# ISD91000_v4_2 register map
File version: 1.0
ISD91000_v4_2 SVD file
Registers are 32-bit, read-write, reset 0x0 unless marked. A register's access mark holds for its fields unless they carry their own. Offsets are from the block's base; lines under a group give offsets from that group; [hi:lo] are bit positions; {n}, {i} and the like mark numbered series; 'fields as' and 'values as' point back to an identical list; <NAME> marks a mode.

## Memory map
0x40004000 WDT size 0x4 — WDT Register Map
0x40008000 RTC size 0x4 — RTC Register Map
0x40008004 OSCFM size 0xC — OSCFM Register Map
0x40010000 TMR blocks up to offset 0x50 — TMR Register Map
0x40030000 SPI0 blocks up to offset 0x3C — SPI Register Map
0x40070000 DPWM size 0x14 — DPWM Register Map
0x400E0000 ADC blocks up to offset 0x48 — ADC Register Map
0x50000000 SYS blocks up to offset 0x11C — SYS Register Map
0x50000300 INT blocks up to offset 0x88 — INT Register Map
0x50004000 GPIO blocks up to offset 0x858 — GPIO Register Map
0x50007000 SPIM blocks up to offset 0x30 — SPIM Register Map
0x50009000 PDMA_CH0 size 0x28 — PDMA Register Map
0x50009100 PDMA_CH1 size 0x28 — PDMA Register Map
0x50009F00 PDMA_GCR blocks up to offset 0x10 — PDMA Register Map
0x5000C000 FMC size 0x18 — FCM Register Map
0xE000E000 SCS blocks up to offset 0x414 — SCS Register Map

## SCS — SCS Register Map
Base 0xE000E000
0x100 NVIC_ISER — IRQ0 ~ IRQ18 Set-enable Control Register
  [15:0] SETENA — Interrupt Set-Enable Bit. The NVIC_ISER register enables interrupts, and shows what interrupts are enabled. Each bit represents an interrupt number from IRQ0 ~ IRQ18 (Vector number from 16 ~ 34). . Write Operation:
    0=No effect. Interrupt Disabled; 1=Interrupt Enabled
0x180 NVIC_ICER — IRQ0 ~ IRQ18 Clear-enable Control Register
  [15:0] CLRENA — Interrupt Clear-Enable Bit. The NVIC_ICER register disables interrupts, and shows what interrupts are enabled. Each bit represents an interrupt number from IRQ0 ~ IRQ18 (Vector number from 16 ~ 34). . Write Operation:
    0=No effect. Interrupt Disabled; 1=Interrupt Disabled. Interrupt Enabled
0x200 NVIC_ISPR — IRQ0 ~ IRQ18 Set-pending Control Register
  [15:0] SETPEND — Interrupt Set-Pending Bit. The NVIC_ISPR register forces interrupts into the pending state, and shows what interrupts are pending. Each bit represents an interrupt number from IRQ0 ~ IRQ18 (Vector number from 16 ~ 34). . Write Operation:
    0=No effect. Interrupt is not pending; 1=Changes interrupt state to pending. Interrupt is pending
0x280 NVIC_ICPR — IRQ0 ~ IRQ18 Clear-pending Control Register
  [15:0] CLRPEND — Interrupt Clear-Pending Bit. The NVIC_ICPR register removes the pending state of associated interrupts, and shows what interrupts are pending. Each bit represents an interrupt number from IRQ0 ~ IRQ18 (Vector number from 16 ~ 34). Write Operation:
    0=No effect. Interrupt is not pending; 1=Removes pending state of an interrupt. Interrupt is pending
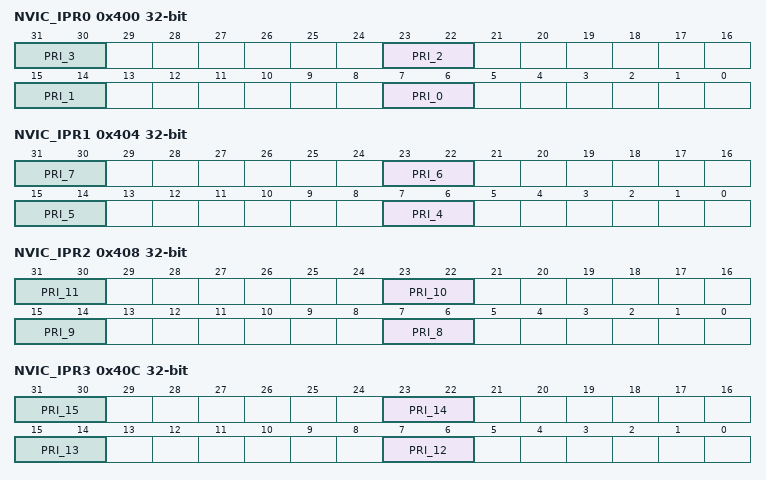
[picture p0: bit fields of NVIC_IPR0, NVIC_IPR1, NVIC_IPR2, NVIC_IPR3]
0x400 NVIC_IPR0 — IRQ0 ~ IRQ3 Priority Control Register
  [8n+7:8n+6] PRI_{n} (n=0..3) — Priority Of IRQ{n} "0" denotes the highest priority and "3" denotes lowest priority
0x404 NVIC_IPR1 — IRQ4 ~ IRQ7 Priority Control Register
  [8n-25:8n-26] PRI_{n} (n=4..7) — Priority Of IRQ{n} "0" denotes the highest priority and "3" denotes lowest priority
0x408 NVIC_IPR2 — IRQ8 ~ IRQ11 Priority Control Register
  [8n-57:8n-58] PRI_{n} (n=8..11) — Priority Of IRQ{n} "0" denotes the highest priority and "3" denotes lowest priority
0x40C NVIC_IPR3 — IRQ12 ~ IRQ15 Priority Control Register
  [8n-89:8n-90] PRI_{n} (n=12..15) — Priority Of IRQ{n} "0" denotes the highest priority and "3" denotes lowest priority
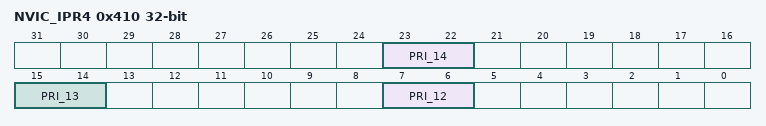
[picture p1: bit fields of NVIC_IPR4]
0x410 NVIC_IPR4 — IRQ16 ~ IRQ18 Priority Control Register
  [23:22] PRI_14 — Priority Of IRQ14 "0" denotes the highest priority and "3" denotes lowest priority
  [15:14] PRI_13 — Priority Of IRQ13 "0" denotes the highest priority and "3" denotes lowest priority
  [7:6] PRI_12 — Priority Of IRQ12 "0" denotes the highest priority and "3" denotes lowest priority
